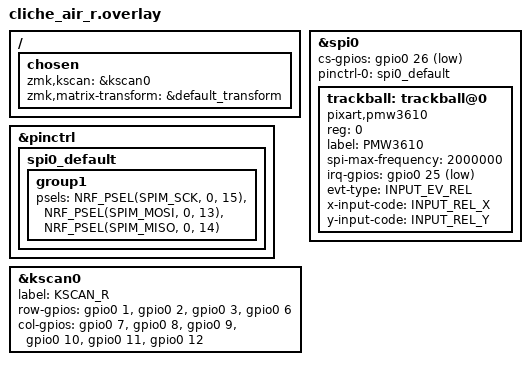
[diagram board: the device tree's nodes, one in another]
/*
 * Cliche Air (Right side / Central)
 * ----------------------------------------
 * Features:
 * - Split central (Right side)
 * - BLE + USB
 * - Trackball PMW3610
 * - RGB widget compatible
 * - No encoder
 */

#include <zephyr/dt-bindings/input/input-event-codes.h>
#include "cliche_air.dtsi"

/* ----------------------------------------
 * SPIピン設定 (SPI0 Default)
 * ---------------------------------------- */
&pinctrl {
	spi0_default: spi0_default {
		group1 {
			psels = <NRF_PSEL(SPIM_SCK, 0, 15)>,  /* SCK  = P0.15 */
			        <NRF_PSEL(SPIM_MOSI, 0, 13)>, /* MOSI = P0.13 */
			        <NRF_PSEL(SPIM_MISO, 0, 14)>; /* MISO = P0.14 */
		};
	};
};

 / {
	chosen {
		zmk,kscan = &kscan0;
		zmk,matrix-transform = &default_transform;
	};
};

/* ----------------------------------------
 * Keyscan Matrix (右手側)
 * ---------------------------------------- */
&kscan0 {
	label = "KSCAN_R";
	row-gpios = <&gpio0 1 (GPIO_ACTIVE_HIGH | GPIO_PULL_DOWN)>,
	            <&gpio0 2 (GPIO_ACTIVE_HIGH | GPIO_PULL_DOWN)>,
	            <&gpio0 3 (GPIO_ACTIVE_HIGH | GPIO_PULL_DOWN)>,
	            <&gpio0 6 (GPIO_ACTIVE_HIGH | GPIO_PULL_DOWN)>;

	col-gpios = <&gpio0 7  (GPIO_ACTIVE_HIGH | GPIO_PULL_UP)>,
	            <&gpio0 8  (GPIO_ACTIVE_HIGH | GPIO_PULL_UP)>,
	            <&gpio0 9  (GPIO_ACTIVE_HIGH | GPIO_PULL_UP)>,
	            <&gpio0 10 (GPIO_ACTIVE_HIGH | GPIO_PULL_UP)>,
	            <&gpio0 11 (GPIO_ACTIVE_HIGH | GPIO_PULL_UP)>,
	            <&gpio0 12 (GPIO_ACTIVE_HIGH | GPIO_PULL_UP)>;
	status = "okay";
};

/* ----------------------------------------
 * SPI bus + Trackball sensor (PMW3610)
 * ---------------------------------------- */
&spi0 {
	status = "okay";
	cs-gpios = <&gpio0 26 GPIO_ACTIVE_LOW>;

	pinctrl-0 = <&spi0_default>;
	pinctrl-names = "default";

	trackball: trackball@0 {
		compatible = "pixart,pmw3610";
		reg = <0>;
		label = "PMW3610";
		spi-max-frequency = <2000000>;
		irq-gpios = <&gpio0 25 GPIO_ACTIVE_LOW>;
		evt-type = <INPUT_EV_REL>;
		x-input-code = <INPUT_REL_X>;
		y-input-code = <INPUT_REL_Y>;
		status = "okay";
	};
};
